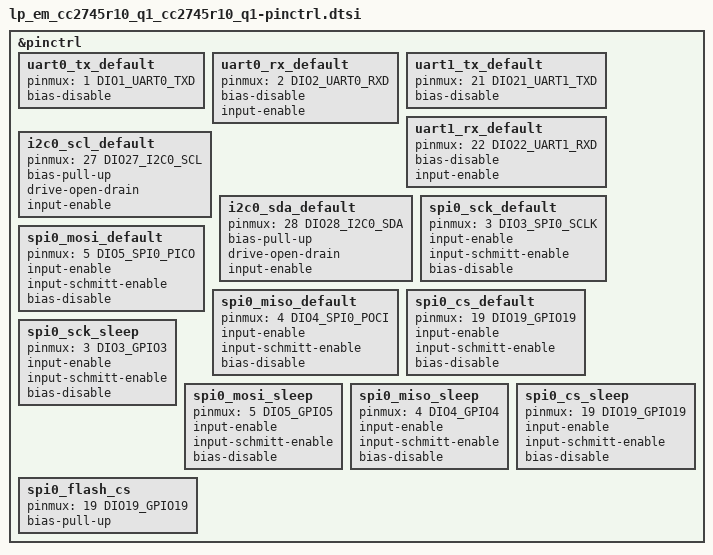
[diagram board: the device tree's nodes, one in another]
/*
 * Copyright (c) 2025 Texas Instruments Incorporated
 * Copyright (c) 2024 BayLibre, SAS
 *
 * SPDX-License-Identifier: Apache-2.0
 */

#include <zephyr/dt-bindings/pinctrl/cc27xx-pinctrl.h>

&pinctrl {
	/* UART0 */
	uart0_tx_default: uart0_tx_default {
		pinmux = <1 DIO1_UART0_TXD>;
		bias-disable;
	};
	uart0_rx_default: uart0_rx_default {
		pinmux = <2 DIO2_UART0_RXD>;
		bias-disable;
		input-enable;
	};

	/* UART1 */
	uart1_tx_default: uart1_tx_default {
		pinmux = <21 DIO21_UART1_TXD>;
		bias-disable;
	};
	uart1_rx_default: uart1_rx_default {
		pinmux = <22 DIO22_UART1_RXD>;
		bias-disable;
		input-enable;
	};

	/* I2C0 */
	i2c0_scl_default: i2c0_scl_default {
		pinmux = <27 DIO27_I2C0_SCL>;
		bias-pull-up;
		drive-open-drain;
		input-enable;
	};
	i2c0_sda_default: i2c0_sda_default {
		pinmux = <28 DIO28_I2C0_SDA>;
		bias-pull-up;
		drive-open-drain;
		input-enable;
	};

	/* SPI0 */
	spi0_sck_default: spi0_sck_default {
		pinmux = <3 DIO3_SPI0_SCLK>;
		input-enable;
		input-schmitt-enable;
		bias-disable;
	};
	spi0_mosi_default: spi0_mosi_default {
		pinmux = <5 DIO5_SPI0_PICO>;
		input-enable;
		input-schmitt-enable;
		bias-disable;
	};
	spi0_miso_default: spi0_miso_default {
		pinmux = <4 DIO4_SPI0_POCI>;
		input-enable;
		input-schmitt-enable;
		bias-disable;
	};
	spi0_cs_default: spi0_cs_default {
		pinmux = <19 DIO19_GPIO19>;
		input-enable;
		input-schmitt-enable;
		bias-disable;
	};

	spi0_sck_sleep: spi0_sck_sleep {
		pinmux = <3 DIO3_GPIO3>;
		input-enable;
		input-schmitt-enable;
		bias-disable;
	};
	spi0_mosi_sleep: spi0_mosi_sleep {
		pinmux = <5 DIO5_GPIO5>;
		input-enable;
		input-schmitt-enable;
		bias-disable;
	};
	spi0_miso_sleep: spi0_miso_sleep {
		pinmux = <4 DIO4_GPIO4>;
		input-enable;
		input-schmitt-enable;
		bias-disable;
	};
	spi0_cs_sleep: spi0_cs_sleep {
		pinmux = <19 DIO19_GPIO19>;
		input-enable;
		input-schmitt-enable;
		bias-disable;
	};

	spi0_flash_cs: spi0_flash_cs {
		pinmux = <19 DIO19_GPIO19>;
		bias-pull-up;
	};
};
